# MDR32FG16S1QI register map
Vendor: Milandr; File version: 1.0
CPU: CM3 r1p1, little endian, MPU, no FPU, 3 interrupt priority bits
Registers are 32-bit, read-write, reset 0x0 unless marked. A register's access mark holds for its fields unless they carry their own. Offsets are from the block's base; [hi:lo] are bit positions; {n}, {i} and the like mark numbered series.

## MDR_UART1 — UART1 interface controller registers
Base 0x40030000
Same registers: MDR_UART2 0x40038000, MDR_UART3 0x400D0000
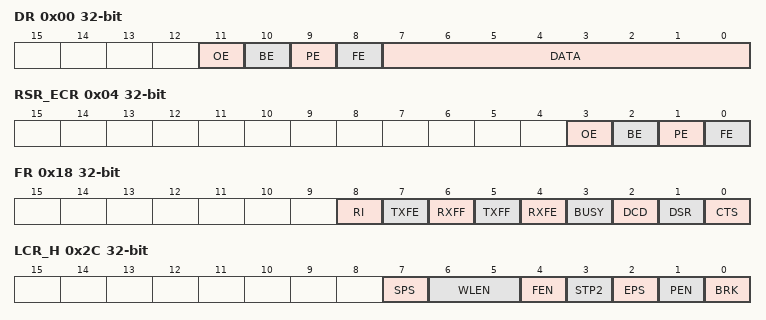
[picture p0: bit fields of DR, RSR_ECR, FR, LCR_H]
0x00 DR wo — UART Data Register
  [11] OE, [10] BE, [9] PE, [8] FE, [7:0] DATA
0x04 RSR_ECR — UART RSR Register
  [3] OE, [2] BE, [1] PE, [0] FE
0x18 FR — UART Flag Register
  [8] RI, [7] TXFE, [6] RXFF, [5] TXFF, [4] RXFE, [3] BUSY, [2] DCD, [1] DSR, [0] CTS
0x20 ILPR
  [7:0] ILPDVSR
0x24 IBRD
  [15:0] BAUD_DIVINT
0x28 FBRD
  [5:0] BAUD_DIVFRAC
0x2C LCR_H — UART LCR_H Register
  [7] SPS, [6:5] WLEN, [4] FEN, [3] STP2, [2] EPS, [1] PEN, [0] BRK
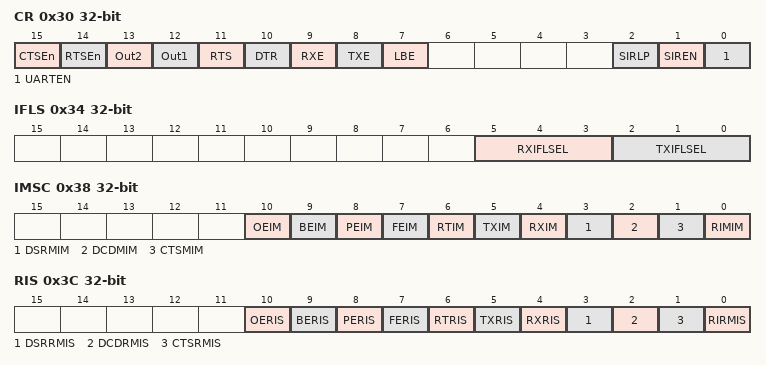
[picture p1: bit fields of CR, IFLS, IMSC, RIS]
0x30 CR — UART Command Register
  [15] CTSEn, [14] RTSEn, [13] Out2, [12] Out1, [11] RTS, [10] DTR, [9] RXE, [8] TXE, [7] LBE, [2] SIRLP, [1] SIREN, [0] UARTEN
0x34 IFLS — UART IFLS Register
  [5:3] RXIFLSEL, [2:0] TXIFLSEL
0x38 IMSC — UART Interrupt Mask Register
  [10] OEIM, [9] BEIM, [8] PEIM, [7] FEIM, [6] RTIM, [5] TXIM, [4] RXIM, [3] DSRMIM, [2] DCDMIM, [1] CTSMIM, [0] RIMIM
0x3C RIS — UART Interrupt Pending Register
  [10] OERIS, [9] BERIS, [8] PERIS, [7] FERIS, [6] RTRIS, [5] TXRIS, [4] RXRIS, [3] DSRRMIS, [2] DCDRMIS, [1] CTSRMIS, [0] RIRMIS
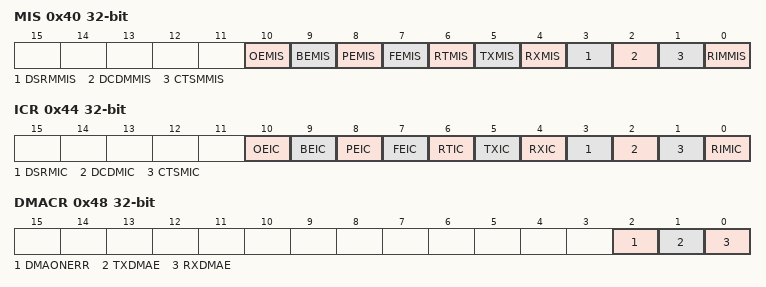
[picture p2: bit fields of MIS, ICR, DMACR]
0x40 MIS — UART Masked Interrupt Pending Register
  [10] OEMIS, [9] BEMIS, [8] PEMIS, [7] FEMIS, [6] RTMIS, [5] TXMIS, [4] RXMIS, [3] DSRMMIS, [2] DCDMMIS, [1] CTSMMIS, [0] RIMMIS
0x44 ICR — UART Interrupt Clear Register
  [10] OEIC, [9] BEIC, [8] PEIC, [7] FEIC, [6] RTIC, [5] TXIC, [4] RXIC, [3] DSRMIC, [2] DCDMIC, [1] CTSMIC, [0] RIMIC
0x48 DMACR — UART DMA Control Register
  [2] DMAONERR, [1] TXDMAE, [0] RXDMAE

## MDR_SSP1 — SSP1 interface controller registers
Base 0x40040000
Same registers: MDR_SSP3 0x40000000, MDR_SSP4 0x40008000, MDR_SSP2 0x400A0000
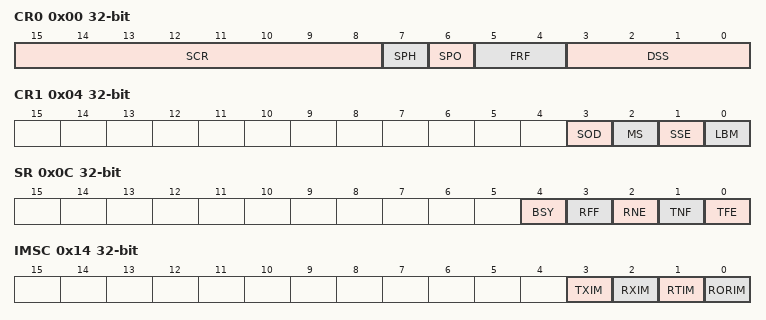
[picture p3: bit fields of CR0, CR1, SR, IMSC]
0x00 CR0 — SSP Control0 Register
  [15:8] SCR, [7] SPH, [6] SPO, [5:4] FRF, [3:0] DSS
0x04 CR1 — SSP Control1 Register
  [3] SOD, [2] MS, [1] SSE, [0] LBM
0x08 DR wo — SSP Data Register
  [15:0] DATA
0x0C SR — SSP Status Register
  [4] BSY, [3] RFF, [2] RNE, [1] TNF, [0] TFE
0x10 CPSR — SSP Clock Prescaler Register
  [7:0] CPSDVSR
0x14 IMSC — SSP Interrupt Mask Register
  [3] TXIM, [2] RXIM, [1] RTIM, [0] RORIM
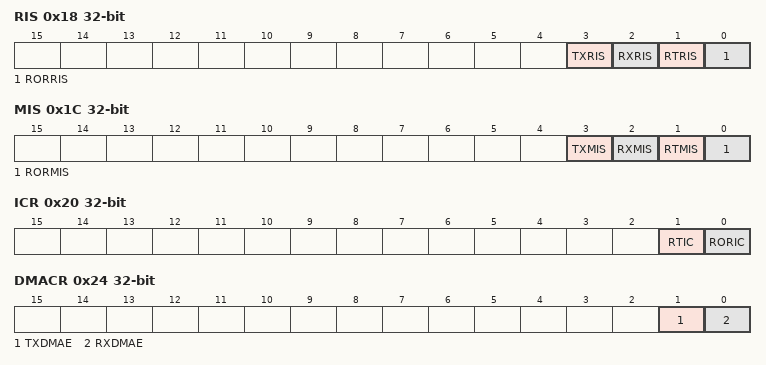
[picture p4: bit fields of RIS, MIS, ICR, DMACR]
0x18 RIS — SSP Interrupt Pending Register
  [3] TXRIS, [2] RXRIS, [1] RTRIS, [0] RORRIS
0x1C MIS — SSP Masked Interrupt Pending Register
  [3] TXMIS, [2] RXMIS, [1] RTMIS, [0] RORMIS
0x20 ICR — SSP Interrupt Clear Register
  [1] RTIC, [0] RORIC
0x24 DMACR — SSP DMA Control Register
  [1] TXDMAE, [0] RXDMAE

## MDR_SDIO — SDIO Controller
Base 0x40048000
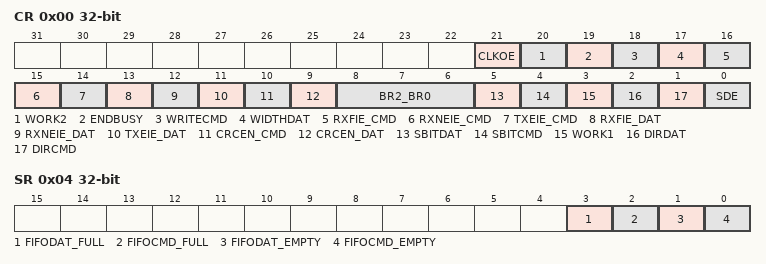
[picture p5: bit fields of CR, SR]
0x00 CR — SDIO Control Register
  [21] CLKOE, [20] WORK2, [19] ENDBUSY, [18] WRITECMD, [17] WIDTHDAT, [16] RXFIE_CMD, [15] RXNEIE_CMD, [14] TXEIE_CMD, [13] RXFIE_DAT, [12] RXNEIE_DAT, [11] TXEIE_DAT, [10] CRCEN_CMD, [9] CRCEN_DAT, [8:6] BR2_BR0, [5] SBITDAT, [4] SBITCMD, [3] WORK1, [2] DIRDAT, [1] DIRCMD, [0] SDE
0x04 SR — SDIO Status Register
  [3] FIFODAT_FULL, [2] FIFOCMD_FULL, [1] FIFODAT_EMPTY, [0] FIFOCMD_EMPTY
0x08 CMDDR — SDIO Command Data Register
  [31:0] RX_FIFO_TX_FIFO
0x0C DATDR — SDIO Data Register
  [31:0] RX_FIFO_TX_FIFO
0x10 CMDCRC — SDIO Command CRC Register
  [6:0] CMDCRC
{0x14+4i} DAT{i}CRC (i=0..3) — SDIO Data{i} CRC Register
  [15:0] DAT{i}CRC
0x24 CMDTransfer — SDIO Command Transfer Register
  [15:0] CMDtransfer
0x28 DATtransfer — SDIO Data Transfer Register
  [15:0] DATtransfer

## MDR_I2C — I2C interface controller registers
Base 0x40050000
0x00 PRL — I2C Prescaler (low byte) Register
  [7:0] PR
0x04 PRH — I2C Prescaler (high byte) Register
  [7:0] PR
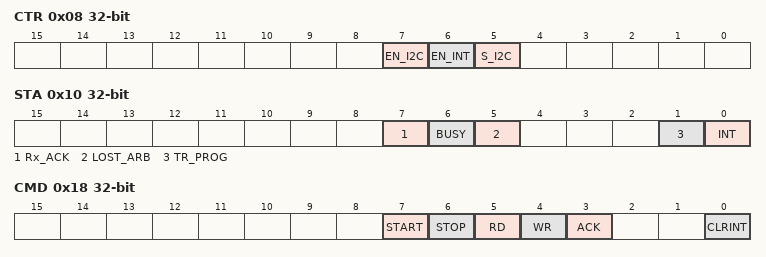
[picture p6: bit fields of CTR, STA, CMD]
0x08 CTR — I2C Control Register
  [7] EN_I2C, [6] EN_INT, [5] S_I2C
0x0C RXD — I2C Received Data Register
  [7:0] RXD
0x10 STA — I2C Status Register
  [7] Rx_ACK, [6] BUSY, [5] LOST_ARB, [1] TR_PROG, [0] INT
0x14 TXD — I2C Transmitted Data Register
  [7:0] TXD
0x18 CMD — I2C Command Register
  [7] START, [6] STOP, [5] RD, [4] WR, [3] ACK, [0] CLRINT
